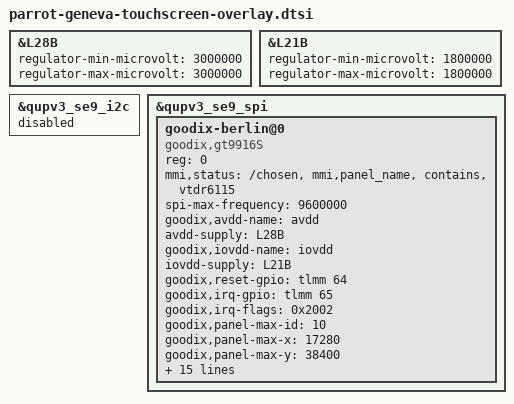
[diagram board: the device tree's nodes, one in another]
&L28B{
	regulator-min-microvolt = <3000000>;
	regulator-max-microvolt = <3000000>;
};

&L21B{
	regulator-min-microvolt = <1800000>;
	regulator-max-microvolt = <1800000>;
};

&qupv3_se9_i2c{
	status = "disabled";
};

&qupv3_se9_spi{
	#address-cells = <1>;
	#size-cells = <0>;
	status = "ok";

	goodix-berlin@0{
		compatible = "goodix,gt9916S";
		reg = <0>;
		mmi,status = "/chosen","mmi,panel_name","contains","vtdr6115";
		spi-max-frequency = <9600000>; /* 4800000,9600000,15000000,19200000 */
		goodix,avdd-name = "avdd";
		avdd-supply = <&L28B>;
		goodix,iovdd-name = "iovdd";
		iovdd-supply = <&L21B>;
		goodix,reset-gpio = <&tlmm 64 0x0>;
		goodix,irq-gpio = <&tlmm 65 0x2002>;
		goodix,irq-flags = <0x2002>; /* 1:trigger rising, 2:trigger falling */
		goodix,panel-max-id = <10>;
		goodix,panel-max-x = <17280>; /* 1080*16 */
		goodix,panel-max-y = <38400>; /* 2400*16 */
		goodix,panel-max-w = <255>;
		goodix,panel-max-p = <4096>;
		pinctrl-names = "pmx_ts_active", "pmx_ts_suspend", "pmx_ts_release";
		pinctrl-0 = <&ts_spi_active>;
		pinctrl-1 = <&ts_spi_int_suspend &ts_spi_reset_suspend>;
		pinctrl-2 = <&ts_spi_release>;
		goodix,firmware-name = "goodix_firmware.bin";
		goodix,config-name = "goodix_cfg_group.bin";
		mmi,power-off-suspend;
		mmi,enable-gestures;
		mmi,usb-charger-detection;
		goodix,gesture-wait-pm;
		goodix,edge-ctrl;
		goodix,interpolation-ctrl;
		mmi,supported_gesture_type = <0x07>;
	};

};
